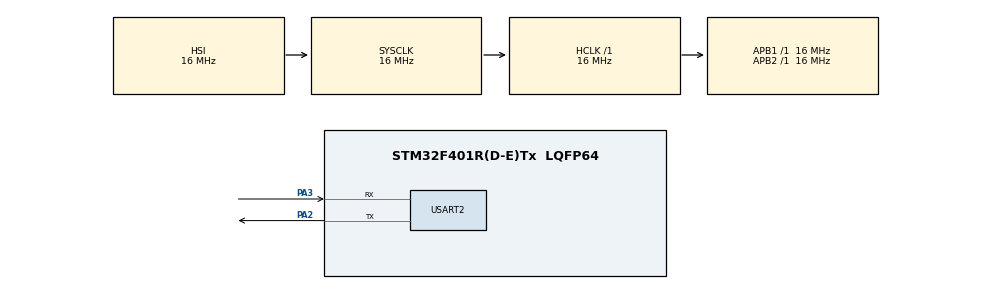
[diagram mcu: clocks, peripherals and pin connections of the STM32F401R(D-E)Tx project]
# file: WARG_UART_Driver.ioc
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Mcu.Family=STM32F4
Mcu.Name=STM32F401R(D-E)Tx
Mcu.Package=LQFP64
NVIC.PriorityGroup=NVIC_PRIORITYGROUP_4
NVIC.USART2_IRQn=true\:0\:0\:false\:false\:true\:true\:true
PA2.Mode=Asynchronous
PA2.Signal=USART2_TX
PA3.Mode=Asynchronous
PA3.Signal=USART2_RX
ProjectManager.HeapSize=0x200
ProjectManager.StackSize=0x400
ProjectManager.TargetToolchain=STM32CubeIDE
RCC.AHBFreq_Value=16000000
RCC.APB1Freq_Value=16000000
RCC.APB2Freq_Value=16000000
RCC.CortexFreq_Value=16000000
RCC.HSE_VALUE=25000000
RCC.HSI_VALUE=16000000
RCC.LSE_VALUE=32768
RCC.SYSCLKFreq_VALUE=16000000
RCC.VCOOutputFreq_Value=192000000
USART2.VirtualMode=VM_ASYNC
board=custom

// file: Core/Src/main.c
/* USER CODE BEGIN Header */
/**
  ******************************************************************************
  * @file           : main.c
  * @brief          : Main program body
  ******************************************************************************
  * @attention
  *
  * Copyright (c) 2022 STMicroelectronics.
  * All rights reserved.
  *
  * This software is licensed under terms that can be found in the LICENSE file
  * in the root directory of this software component.
  * If no LICENSE file comes with this software, it is provided AS-IS.
  *
  ******************************************************************************
  */
/* USER CODE END Header */
#include "main.h"
#include <stdio.h>
#include <string.h>
#include <stdlib.h>

UART_HandleTypeDef huart2;

void SystemClock_Config(void);
static void MX_GPIO_Init(void);
static void MX_USART2_UART_Init(void);

/* USER CODE BEGIN 0 */

//Creates the fijo and foji struct
//The reason there are 2 different gpsCoordinates structs is to minimize the size of the fijo struct
struct gpsCoordinatesFOJI{
	double lattitude;
	double longtitude;
	double altitude;
};

struct gpsCoordinatesFIJO{
	double lattitude;
	double longtitude;
};

struct eulerAnglesOfPlane{
	float yaw;
	float pitch;
	float roll;
};

//Should be 36 bytes but because of padding its really 40 bytes
//Flight Controller Out Jetson In
 struct foji{
	struct gpsCoordinatesFOJI gpsCoord;
	struct eulerAnglesOfPlane anglesOfPlane;
};

//Should be 19 bytes but because of padding its really 24 bytes
//Flight Controller In Jetson Out
struct fijo{
	_Bool takeoffCommand;
	_Bool qrScanFlag;
	_Bool detectFlag;
	struct gpsCoordinatesFIJO gpsCoord;
};

const uint8_t START_BYTE = 0x24;

void sendFOJI(){
	//Get msg_to_jetson from telemetry manager
	struct foji msg_to_jetson;
	HAL_UART_Transmit(&huart2, &START_BYTE, sizeof(START_BYTE), HAL_MAX_DELAY);
	HAL_UART_Transmit(&huart2, &msg_to_jetson, sizeof(struct foji), HAL_MAX_DELAY);

}

//Creates byte array
uint8_t buf[sizeof(struct fijo)];

//Creates the byte used to confirm if the received bytes are a valid message
uint8_t check;

void readFIJO(){
	struct fijo msg_from_jetson;

	//Receives a byte to check if its the same as START_BYTE
	HAL_UART_Receive_IT(&huart2, &check, 1);

	if(check == START_BYTE){

		//Convert the byte array into an fijo struct
		struct fijo *byteToStruct = (struct fijo*)buf;
		msg_from_jetson.takeoffCommand = byteToStruct->takeoffCommand;
		msg_from_jetson.qrScanFlag = byteToStruct->qrScanFlag;
		msg_from_jetson.detectFlag = byteToStruct->detectFlag;
		msg_from_jetson.gpsCoord.lattitude = byteToStruct->gpsCoord.lattitude;
		msg_from_jetson.gpsCoord.longtitude = byteToStruct->gpsCoord.longtitude;

		//Send msg_from_jetson into telemetry manager

		//Resets the check byte
		check = 0;
	}
}
/* USER CODE END 0 */

int main(void)
{

  /* MCU Configuration--------------------------------------------------------*/

  /* Reset of all peripherals, Initializes the Flash interface and the Systick. */
  HAL_Init();

  /* Configure the system clock */
  SystemClock_Config();

  /* Initialize all configured peripherals */
  MX_GPIO_Init();
  MX_USART2_UART_Init();

  /* Infinite loop */
  while (1)
  {

    /* USER CODE BEGIN 3 */
	  sendFOJI();
	  readFIJO();
  }
  /* USER CODE END 3 */
}

void SystemClock_Config(void)
{
  RCC_OscInitTypeDef RCC_OscInitStruct = {0};
  RCC_ClkInitTypeDef RCC_ClkInitStruct = {0};

  /** Configure the main internal regulator output voltage
  */
  __HAL_RCC_PWR_CLK_ENABLE();
  __HAL_PWR_VOLTAGESCALING_CONFIG(PWR_REGULATOR_VOLTAGE_SCALE2);
  /** Initializes the RCC Oscillators according to the specified parameters
  * in the RCC_OscInitTypeDef structure.
  */
  RCC_OscInitStruct.OscillatorType = RCC_OSCILLATORTYPE_HSI;
  RCC_OscInitStruct.HSIState = RCC_HSI_ON;
  RCC_OscInitStruct.HSICalibrationValue = RCC_HSICALIBRATION_DEFAULT;
  RCC_OscInitStruct.PLL.PLLState = RCC_PLL_NONE;
  if (HAL_RCC_OscConfig(&RCC_OscInitStruct) != HAL_OK)
  {
    Error_Handler();
  }
  /** Initializes the CPU, AHB and APB buses clocks
  */
  RCC_ClkInitStruct.ClockType = RCC_CLOCKTYPE_HCLK|RCC_CLOCKTYPE_SYSCLK
                              |RCC_CLOCKTYPE_PCLK1|RCC_CLOCKTYPE_PCLK2;
  RCC_ClkInitStruct.SYSCLKSource = RCC_SYSCLKSOURCE_HSI;
  RCC_ClkInitStruct.AHBCLKDivider = RCC_SYSCLK_DIV1;
  RCC_ClkInitStruct.APB1CLKDivider = RCC_HCLK_DIV1;
  RCC_ClkInitStruct.APB2CLKDivider = RCC_HCLK_DIV1;

  if (HAL_RCC_ClockConfig(&RCC_ClkInitStruct, FLASH_LATENCY_0) != HAL_OK)
  {
    Error_Handler();
  }
}

static void MX_USART2_UART_Init(void)
{

  huart2.Instance = USART2;
  huart2.Init.BaudRate = 115200;
  huart2.Init.WordLength = UART_WORDLENGTH_8B;
  huart2.Init.StopBits = UART_STOPBITS_1;
  huart2.Init.Parity = UART_PARITY_NONE;
  huart2.Init.Mode = UART_MODE_TX_RX;
  huart2.Init.HwFlowCtl = UART_HWCONTROL_NONE;
  huart2.Init.OverSampling = UART_OVERSAMPLING_16;
  if (HAL_UART_Init(&huart2) != HAL_OK)
  {
    Error_Handler();
  }

}

static void MX_GPIO_Init(void)
{

  /* GPIO Ports Clock Enable */
  __HAL_RCC_GPIOA_CLK_ENABLE();

}

/* USER CODE BEGIN 4 */
void HAL_UART_RxCpltCallback(UART_HandleTypeDef *huart){
	//If check is the correct byte, the following bytes can be stored in the buffer array to then be parsed into an fijo struct
	if(check == START_BYTE){
		HAL_UART_Receive(&huart2, buf, sizeof(buf), HAL_MAX_DELAY);
	}
}
/* USER CODE END 4 */

void Error_Handler(void)
{
  __disable_irq();
  while (1)
  {
  }
}
